# ing920 register map
Vendor: INGChips; Series: ing920xx; File version: 1.0
CPU: CM3 r2p1, little endian, no MPU, no FPU, 2 interrupt priority bits
Registers are 32-bit, read-write, reset 0x0 unless marked. A register's access mark holds for its fields unless they carry their own. Offsets are from the block's base; [hi:lo] are bit positions; {n}, {i} and the like mark numbered series.

## aon2_ctrl
Base 0x40100000
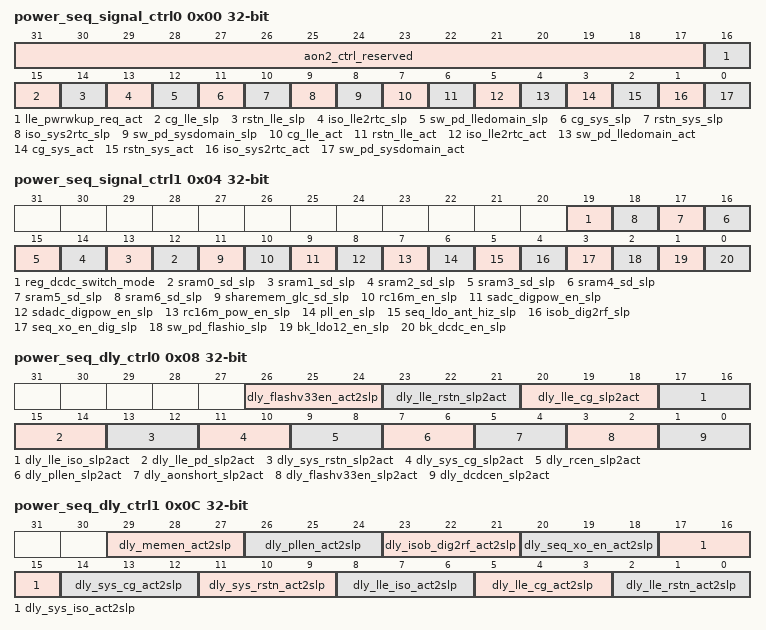
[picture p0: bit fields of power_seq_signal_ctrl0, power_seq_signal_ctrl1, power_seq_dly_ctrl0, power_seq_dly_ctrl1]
0x00 power_seq_signal_ctrl0 — reg description:
  [31:17] aon2_ctrl_reserved — reg description:
  [16] lle_pwrwkup_req_act — reg description:
  [15] cg_lle_slp — reg description:
  [14] rstn_lle_slp — reg description:
  [13] iso_lle2rtc_slp — reg description:
  [12] sw_pd_lledomain_slp — reg description:
  [11] cg_sys_slp — reg description:
  [10] rstn_sys_slp — reg description:
  [9] iso_sys2rtc_slp — reg description:
  [8] sw_pd_sysdomain_slp — reg description:
  [7] cg_lle_act — reg description:
  [6] rstn_lle_act — reg description:
  [5] iso_lle2rtc_act — reg description:
  [4] sw_pd_lledomain_act — reg description:
  [3] cg_sys_act — reg description:
  [2] rstn_sys_act — reg description:
  [1] iso_sys2rtc_act — reg description:
  [0] sw_pd_sysdomain_act — reg description:
0x04 power_seq_signal_ctrl1 — reg description:
  [19] reg_dcdc_switch_mode — reg description:
  [n+12] sram{n}_sd_slp (n=0..6) — reg description:
  [11] sharemem_glc_sd_slp — reg description:
  [10] rc16m_en_slp — reg description:
  [9] sadc_digpow_en_slp — reg description:
  [8] sdadc_digpow_en_slp — reg description:
  [7] rc16m_pow_en_slp — reg description:
  [6] pll_en_slp — reg description:
  [5] seq_ldo_ant_hiz_slp — reg description:
  [4] isob_dig2rf_slp — reg description:
  [3] seq_xo_en_dig_slp — reg description:
  [2] sw_pd_flashio_slp — reg description:
  [1] bk_ldo12_en_slp — reg description:
  [0] bk_dcdc_en_slp — reg description:
0x08 power_seq_dly_ctrl0 — reg description:
  [26:24] dly_flashv33en_act2slp — reg description:
  [23:21] dly_lle_rstn_slp2act — reg description:
  [20:18] dly_lle_cg_slp2act — reg description:
  [17:16] dly_lle_iso_slp2act — reg description:
  [15:14] dly_lle_pd_slp2act — reg description:
  [13:12] dly_sys_rstn_slp2act — reg description:
  [11:10] dly_sys_cg_slp2act — reg description:
  [9:8] dly_rcen_slp2act — reg description:
  [7:6] dly_pllen_slp2act — reg description:
  [5:4] dly_aonshort_slp2act — reg description:
  [3:2] dly_flashv33en_slp2act — reg description:
  [1:0] dly_dcdcen_slp2act — reg description:
0x0C power_seq_dly_ctrl1 — reg description:
  [29:27] dly_memen_act2slp — reg description:
  [26:24] dly_pllen_act2slp — reg description:
  [23:21] dly_isob_dig2rf_act2slp — reg description:
  [20:18] dly_seq_xo_en_act2slp — reg description:
  [17:15] dly_sys_iso_act2slp — reg description:
  [14:12] dly_sys_cg_act2slp — reg description:
  [11:9] dly_sys_rstn_act2slp — reg description:
  [8:6] dly_lle_iso_act2slp — reg description:
  [5:3] dly_lle_cg_act2slp — reg description:
  [2:0] dly_lle_rstn_act2slp — reg description:
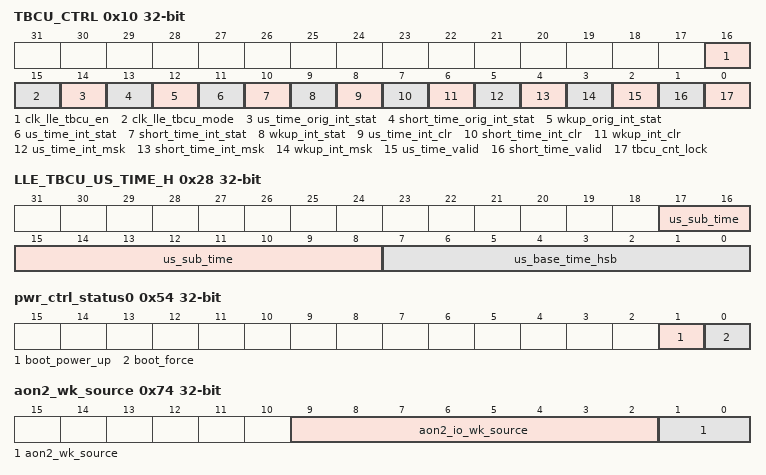
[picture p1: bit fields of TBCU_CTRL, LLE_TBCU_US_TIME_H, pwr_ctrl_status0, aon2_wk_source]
0x10 TBCU_CTRL — reg description:
  [16] clk_lle_tbcu_en — reg description:
  [15] clk_lle_tbcu_mode — reg description:
  [14] us_time_orig_int_stat — reg description:
  [13] short_time_orig_int_stat — reg description:
  [12] wkup_orig_int_stat — reg description:
  [11] us_time_int_stat — reg description:
  [10] short_time_int_stat — reg description:
  [9] wkup_int_stat — reg description:
  [8] us_time_int_clr — reg description:
  [7] short_time_int_clr — reg description:
  [6] wkup_int_clr — reg description:
  [5] us_time_int_msk — reg description:
  [4] short_time_int_msk — reg description:
  [3] wkup_int_msk — reg description:
  [2] us_time_valid — reg description:
  [1] short_time_valid — reg description:
  [0] tbcu_cnt_lock — reg description:
0x14 LLE_TBCU_LOCK_BASETSCNT_LSB — reg description:
  [31:0] bts_lock_cnt_lsb
0x18 LLE_TBCU_LOCK_BASETSCNT_HSB — reg description:
  [7:0] bts_lock_cnt_hsb
0x1C LLE_TBCU_LOCK_SUBTSCNT — reg description:
  [9:0] sts_lock_cnt
0x20 LLE_TBCU_SHORT_TIME — reg description:
  [31:0] short_time
0x24 LLE_TBCU_US_TIME_L — reg description:
  [31:0] us_base_time_lsb
0x28 LLE_TBCU_US_TIME_H — reg description:
  [17:8] us_sub_time — reg description:
  [7:0] us_base_time_hsb — reg description:
0x2C pwr_ctrl0 — reg description:
0x30 aon1_reg4 — reg description:
{0x1C+4i} aon1_reg{i} (i=6..10) — reg description:
0x48 aon1_reg_rd11 — reg description:
  [31:0] aon1_rtc_cnt_lsb
0x4C aon1_reg_rd12 — reg description:
  [10:0] aon1_rtc_cnt_msb
0x50 aon1_reg_rd13 — reg description:
  [31:0] cnt_slp
0x54 pwr_ctrl_status0 — reg description:
  [1] boot_power_up — reg description:
  [0] boot_force — reg description:
0x58 sys_wakeup_pol0 — reg description:
  [31:0] reg_wakeup_pol_31to0
0x5C sys_wakeup_pol1 — reg description:
  [3:0] reg_wakeup_pol_msb
0x60 sys_wakeup_en0 — reg description:
  [31:0] reg_wakeup_en_31to0
0x64 sys_wakeup_en1 — reg description:
  [3:0] reg_wakeup_en_msb
0x68 sys_wakeup_mode0 — reg description:
  [31:0] reg_wakeup_mode_0
0x6C sys_wakeup_mode1 — reg description:
  [31:0] reg_wakeup_mode_1
0x70 sys_wakeup_mode2 — reg description:
  [7:0] reg_wakeup_mode_2
0x74 aon2_wk_source — reg description:
  [9:2] aon2_io_wk_source — reg description:
  [1:0] aon2_wk_source — reg description:
0x78 aon2_io_aon_i_low — reg description:
0x7C aon2_io_aon_i_high — reg description:
  [3:0] aon2_io_aon_i_high
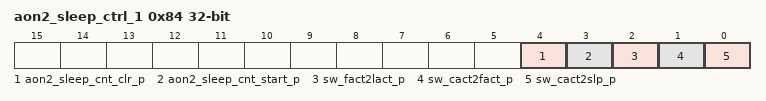
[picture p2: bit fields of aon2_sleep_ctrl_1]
0x84 aon2_sleep_ctrl_1 — reg description:
  [4] aon2_sleep_cnt_clr_p — reg description:
  [3] aon2_sleep_cnt_start_p — reg description:
  [2] sw_fact2lact_p — reg description:
  [1] sw_cact2fact_p — reg description:
  [0] sw_cact2slp_p — reg description:
0x88 aon2_sleep_cnt_rd — reg description:
  [31:0] aon2_sleep_cnt
